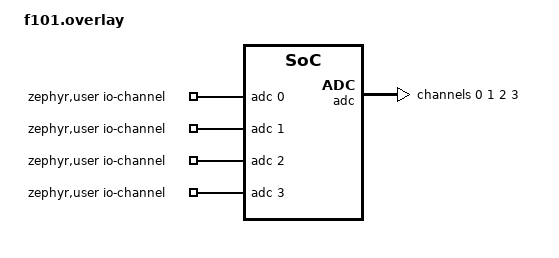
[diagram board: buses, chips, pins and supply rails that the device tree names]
/*
 * Copyright (c) 2026 Yuzuki Tsuru
 * SPDX-License-Identifier: Apache-2.0
 */

#include <zephyr/dt-bindings/adc/adc.h>

/* machine.WDT */
/ {
	aliases {
		watchdog0 = &wdt;
	};

	/* machine.ADC: the channels listed here, in this order, are ADC(0).. */
	zephyr,user {
		io-channels = <&adc 0>, <&adc 1>, <&adc 2>, <&adc 3>;
	};
};

&adc {
	#address-cells = <1>;
	#size-cells = <0>;

	channel@0 {
		reg = <0>;
		zephyr,gain = "ADC_GAIN_1";
		zephyr,reference = "ADC_REF_INTERNAL";
		zephyr,acquisition-time = <ADC_ACQ_TIME_DEFAULT>;
		zephyr,resolution = <12>;
	};
	channel@1 {
		reg = <1>;
		zephyr,gain = "ADC_GAIN_1";
		zephyr,reference = "ADC_REF_INTERNAL";
		zephyr,acquisition-time = <ADC_ACQ_TIME_DEFAULT>;
		zephyr,resolution = <12>;
	};
	channel@2 {
		reg = <2>;
		zephyr,gain = "ADC_GAIN_1";
		zephyr,reference = "ADC_REF_INTERNAL";
		zephyr,acquisition-time = <ADC_ACQ_TIME_DEFAULT>;
		zephyr,resolution = <12>;
	};
	channel@3 {
		reg = <3>;
		zephyr,gain = "ADC_GAIN_1";
		zephyr,reference = "ADC_REF_INTERNAL";
		zephyr,acquisition-time = <ADC_ACQ_TIME_DEFAULT>;
		zephyr,resolution = <12>;
	};
};
